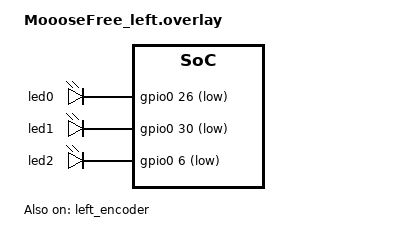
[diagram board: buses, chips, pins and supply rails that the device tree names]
#include "MoooseFree.dtsi"

&left_encoder {
    status = "okay";
};


//&kscan0 {
//    interrupt-gpios = <&xiao_d 10 (GPIO_ACTIVE_HIGH | GPIO_PULL_DOWN) >;
//    gpios
//        = <&xiao_d 1 GPIO_ACTIVE_HIGH>
//        , <&xiao_d 2 GPIO_ACTIVE_HIGH>
//        , <&xiao_d 3 GPIO_ACTIVE_HIGH>
//        , <&xiao_d 7 GPIO_ACTIVE_HIGH>
//        , <&xiao_d 8 GPIO_ACTIVE_HIGH>
//        , <&xiao_d 9 GPIO_ACTIVE_HIGH>
//        ;
//};


/ {
    aliases {
        led-red = &led0;
        led-green = &led1;
        led-blue = &led2;
    };

    leds {
        compatible = "gpio-leds";
        status = "okay";
        led0: led_0 {
            gpios = <&gpio0 26 GPIO_ACTIVE_LOW>;  // red LED, connected to P0.26
        };
        led1: led_1 {
            gpios = <&gpio0 30 GPIO_ACTIVE_LOW>;  // green LED, connected to P0.30
        };
        led2: led_2 {
            gpios = <&gpio0 6 GPIO_ACTIVE_LOW>;  // blue LED, connected to P0.06
        };
    };
};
